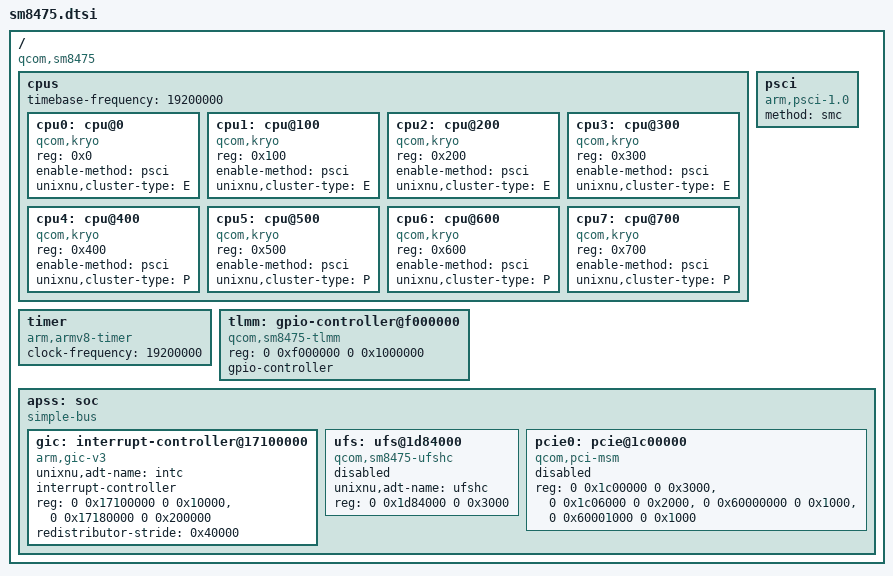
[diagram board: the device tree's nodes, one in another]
/ {
    #address-cells = <2>;
    #size-cells = <2>;
    compatible = "qcom,sm8475";
    cpus {
        #address-cells = <1>;
        #size-cells = <0>;
        timebase-frequency = <19200000>;
        cpu0: cpu@0 { device_type = "cpu"; compatible = "qcom,kryo"; reg = <0x0>; enable-method = "psci"; unixnu,cluster-type = "E"; };
        cpu1: cpu@100 { device_type = "cpu"; compatible = "qcom,kryo"; reg = <0x100>; enable-method = "psci"; unixnu,cluster-type = "E"; };
        cpu2: cpu@200 { device_type = "cpu"; compatible = "qcom,kryo"; reg = <0x200>; enable-method = "psci"; unixnu,cluster-type = "E"; };
        cpu3: cpu@300 { device_type = "cpu"; compatible = "qcom,kryo"; reg = <0x300>; enable-method = "psci"; unixnu,cluster-type = "E"; };
        cpu4: cpu@400 { device_type = "cpu"; compatible = "qcom,kryo"; reg = <0x400>; enable-method = "psci"; unixnu,cluster-type = "P"; };
        cpu5: cpu@500 { device_type = "cpu"; compatible = "qcom,kryo"; reg = <0x500>; enable-method = "psci"; unixnu,cluster-type = "P"; };
        cpu6: cpu@600 { device_type = "cpu"; compatible = "qcom,kryo"; reg = <0x600>; enable-method = "psci"; unixnu,cluster-type = "P"; };
        cpu7: cpu@700 { device_type = "cpu"; compatible = "qcom,kryo"; reg = <0x700>; enable-method = "psci"; unixnu,cluster-type = "P"; };
    };
    psci { compatible = "arm,psci-1.0"; method = "smc"; };
    timer { compatible = "arm,armv8-timer"; clock-frequency = <19200000>; };
    tlmm: gpio-controller@f000000 {
        compatible = "qcom,sm8475-tlmm";
        reg = <0 0xf000000 0 0x1000000>;
        gpio-controller;
        #gpio-cells = <2>;
    };
    apss: soc {
        compatible = "simple-bus";
        #address-cells = <2>;
        #size-cells = <2>;
        ranges;
        gic: interrupt-controller@17100000 {
            compatible = "arm,gic-v3";
            unixnu,adt-name = "intc";
            #interrupt-cells = <3>;
            interrupt-controller;
            #address-cells = <0>;
            reg = <0 0x17100000 0 0x10000>, <0 0x17180000 0 0x200000>;
            redistributor-stride = /bits/ 64 <0x40000>;
        };
        ufs: ufs@1d84000 {
            compatible = "qcom,sm8475-ufshc", "qcom,sm8450-ufshc";
            unixnu,adt-name = "ufshc";
            reg = <0 0x1d84000 0 0x3000>;
            status = "disabled";
        };
        pcie0: pcie@1c00000 {
            compatible = "qcom,pci-msm";
            reg = <0 0x1c00000 0 0x3000>, <0 0x1c06000 0 0x2000>,
                  <0 0x60000000 0 0x1000>, <0 0x60001000 0 0x1000>;
            reg-names = "parf", "phy", "dbi", "iatu";
            status = "disabled";
        };
    };
};
